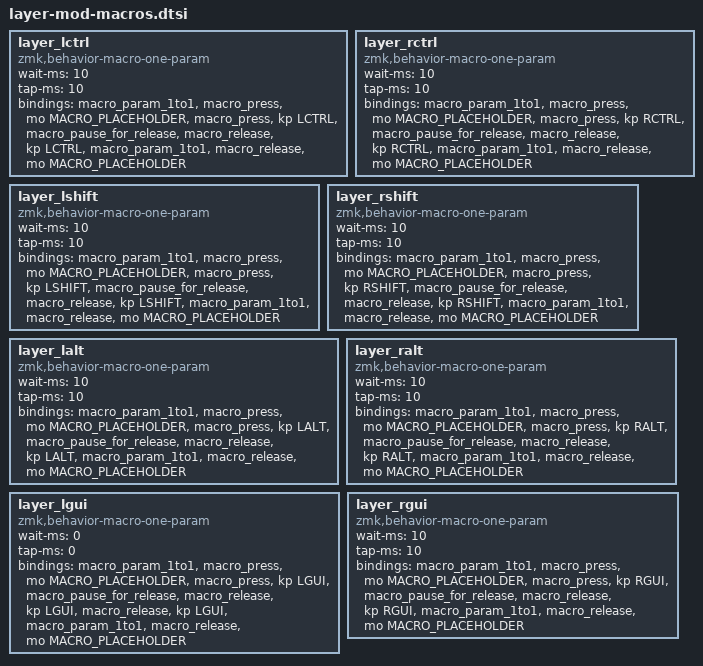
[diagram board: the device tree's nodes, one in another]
// Layer + modifier hold macros (parameterized)
layer_lctrl: layer_lctrl {
    compatible = "zmk,behavior-macro-one-param";
    wait-ms = <10>;
    tap-ms = <10>;
    #binding-cells = <1>;
    bindings
        = <&macro_param_1to1>
        , <&macro_press &mo MACRO_PLACEHOLDER>
        , <&macro_press &kp LCTRL>
        , <&macro_pause_for_release>
        , <&macro_release &kp LCTRL>
        , <&macro_param_1to1>
        , <&macro_release &mo MACRO_PLACEHOLDER>
        ;
};

layer_rctrl: layer_rctrl {
    compatible = "zmk,behavior-macro-one-param";
    wait-ms = <10>;
    tap-ms = <10>;
    #binding-cells = <1>;
    bindings
        = <&macro_param_1to1>
        , <&macro_press &mo MACRO_PLACEHOLDER>
        , <&macro_press &kp RCTRL>
        , <&macro_pause_for_release>
        , <&macro_release &kp RCTRL>
        , <&macro_param_1to1>
        , <&macro_release &mo MACRO_PLACEHOLDER>
        ;
};

layer_lshift: layer_lshift {
    compatible = "zmk,behavior-macro-one-param";
    wait-ms = <10>;
    tap-ms = <10>;
    #binding-cells = <1>;
    bindings
        = <&macro_param_1to1>
        , <&macro_press &mo MACRO_PLACEHOLDER>
        , <&macro_press &kp LSHIFT>
        , <&macro_pause_for_release>
        , <&macro_release &kp LSHIFT>
        , <&macro_param_1to1>
        , <&macro_release &mo MACRO_PLACEHOLDER>
        ;
};

layer_rshift: layer_rshift {
    compatible = "zmk,behavior-macro-one-param";
    wait-ms = <10>;
    tap-ms = <10>;
    #binding-cells = <1>;
    bindings
        = <&macro_param_1to1>
        , <&macro_press &mo MACRO_PLACEHOLDER>
        , <&macro_press &kp RSHIFT>
        , <&macro_pause_for_release>
        , <&macro_release &kp RSHIFT>
        , <&macro_param_1to1>
        , <&macro_release &mo MACRO_PLACEHOLDER>
        ;
};

layer_lalt: layer_lalt {
    compatible = "zmk,behavior-macro-one-param";
    wait-ms = <10>;
    tap-ms = <10>;
    #binding-cells = <1>;
    bindings
        = <&macro_param_1to1>
        , <&macro_press &mo MACRO_PLACEHOLDER>
        , <&macro_press &kp LALT>
        , <&macro_pause_for_release>
        , <&macro_release &kp LALT>
        , <&macro_param_1to1>
        , <&macro_release &mo MACRO_PLACEHOLDER>
        ;
};

layer_ralt: layer_ralt {
    compatible = "zmk,behavior-macro-one-param";
    wait-ms = <10>;
    tap-ms = <10>;
    #binding-cells = <1>;
    bindings
        = <&macro_param_1to1>
        , <&macro_press &mo MACRO_PLACEHOLDER>
        , <&macro_press &kp RALT>
        , <&macro_pause_for_release>
        , <&macro_release &kp RALT>
        , <&macro_param_1to1>
        , <&macro_release &mo MACRO_PLACEHOLDER>
        ;
};

/*
 * layer_lgui: Activates a layer and holds LGUI modifier simultaneously
 * 
 * This macro activates a momentary layer while holding the LGUI (Left GUI/Windows/Command) modifier.
 * When the key is released, both the layer and modifier are released.
 * 
 * The double release of LGUI is intentional to prevent stuck modifier issues.
 */
layer_lgui: layer_lgui {
    compatible = "zmk,behavior-macro-one-param";
    wait-ms = <0>;
    tap-ms = <0>;
    #binding-cells = <1>;
    bindings
        = <&macro_param_1to1>
        , <&macro_press &mo MACRO_PLACEHOLDER>
        , <&macro_press &kp LGUI>
        , <&macro_pause_for_release>
        , <&macro_release &kp LGUI>
        , <&macro_release &kp LGUI>  /* Double release to ensure modifier is cleared */
        , <&macro_param_1to1>
        , <&macro_release &mo MACRO_PLACEHOLDER>
        ;
};

layer_rgui: layer_rgui {
    compatible = "zmk,behavior-macro-one-param";
    wait-ms = <10>;
    tap-ms = <10>;
    #binding-cells = <1>;
    bindings
        = <&macro_param_1to1>
        , <&macro_press &mo MACRO_PLACEHOLDER>
        , <&macro_press &kp RGUI>
        , <&macro_pause_for_release>
        , <&macro_release &kp RGUI>
        , <&macro_param_1to1>
        , <&macro_release &mo MACRO_PLACEHOLDER>
        ;
};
